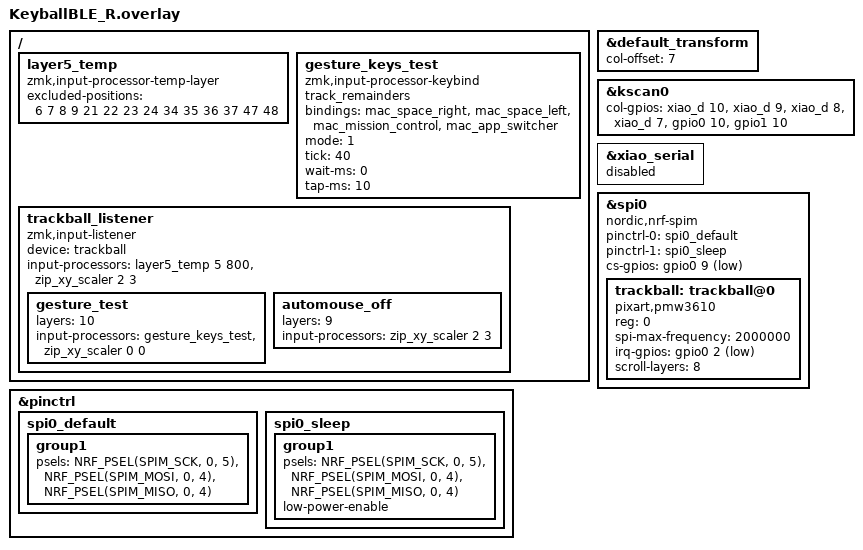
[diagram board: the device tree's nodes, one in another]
#include "KeyballBLE.dtsi"
#include <input/processors.dtsi>
#include <input/processors/zmk-input-processor-keybind.dtsi>

&default_transform {
    col-offset = <7>;
};

&kscan0 {
    col-gpios
        = <&xiao_d 10 GPIO_ACTIVE_HIGH>
        , <&xiao_d 9 GPIO_ACTIVE_HIGH>
        , <&xiao_d 8 GPIO_ACTIVE_HIGH>
        , <&xiao_d 7 GPIO_ACTIVE_HIGH>
        , <&gpio0 10 GPIO_ACTIVE_HIGH>
        , <&gpio1 10 GPIO_ACTIVE_HIGH>
        ;
};

/ {
    layer5_temp: layer5_temp {
        compatible = "zmk,input-processor-temp-layer";
        #input-processor-cells = <2>;

        excluded-positions = <6 7 8 9 21 22 23 24 34 35 36 37 47 48>;
    };

    gesture_keys_test: gesture_keys_test {
        compatible = "zmk,input-processor-keybind";
        #input-processor-cells = <0>;
        track_remainders;
        bindings = <&mac_space_right>, <&mac_space_left>, <&mac_mission_control>, <&mac_app_switcher>;
        mode = <1>;
        tick = <40>;
        wait-ms = <0>;
        tap-ms = <10>;
    };

    trackball_listener {
        compatible = "zmk,input-listener";
        device = <&trackball>;

gesture_test {
    layers = <10>;
    input-processors = <&gesture_keys_test>, <&zip_xy_scaler 0 0>;
};

        input-processors = <&layer5_temp 5 800>, <&zip_xy_scaler 2 3>;

        automouse_off {
            layers = <9>;
            input-processors = <&zip_xy_scaler 2 3>;
        };
    };
};

&pinctrl {
    spi0_default: spi0_default {
        group1 {
            psels = <NRF_PSEL(SPIM_SCK, 0, 5)>,
                <NRF_PSEL(SPIM_MOSI, 0, 4)>,
                <NRF_PSEL(SPIM_MISO, 0, 4)>;
        };
    };

    spi0_sleep: spi0_sleep {
        group1 {
            psels = <NRF_PSEL(SPIM_SCK, 0, 5)>,
                <NRF_PSEL(SPIM_MOSI, 0, 4)>,
                <NRF_PSEL(SPIM_MISO, 0, 4)>;
            low-power-enable;
        };
    };
};

&xiao_serial { status = "disabled"; };

&spi0 {
    status = "okay";
    compatible = "nordic,nrf-spim";
    pinctrl-0 = <&spi0_default>;
    pinctrl-1 = <&spi0_sleep>;
    pinctrl-names = "default", "sleep";
    cs-gpios = <&gpio0 9 GPIO_ACTIVE_LOW>;

    trackball: trackball@0 {
        status = "okay";
        compatible = "pixart,pmw3610";
        reg = <0>;
        spi-max-frequency = <2000000>;
        irq-gpios = <&gpio0 2 (GPIO_ACTIVE_LOW | GPIO_PULL_UP)>;
        scroll-layers = <8>;
    };
};
